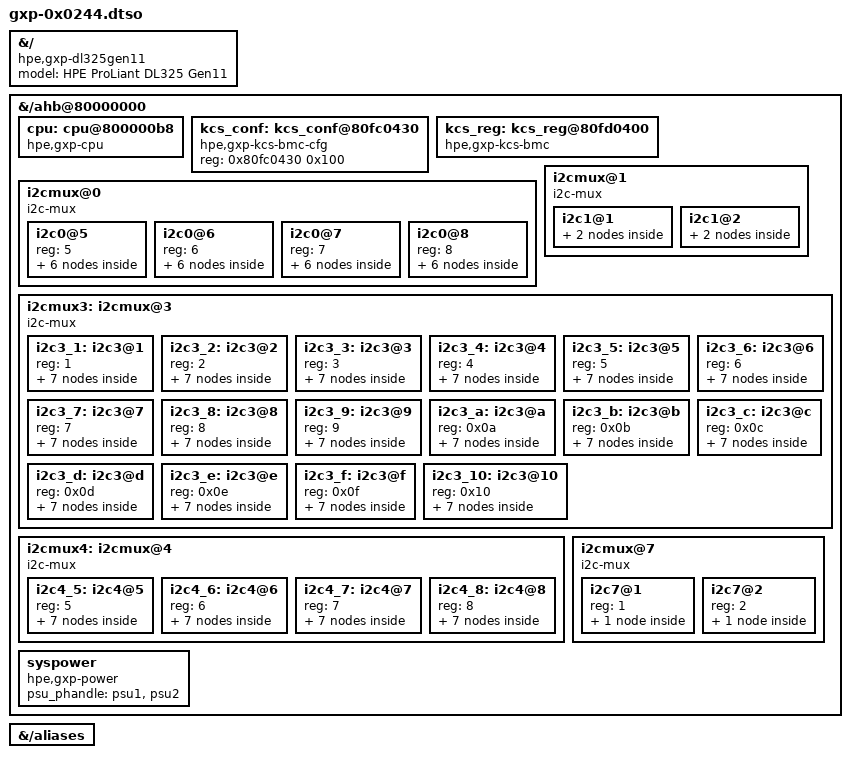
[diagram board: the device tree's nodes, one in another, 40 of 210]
/dts-v1/;
/plugin/;
&{/} {
    model = "HPE ProLiant DL325 Gen11";
    compatible = "hpe,gxp-dl325gen11", "hpe,gxp";
};
&{/ahb@80000000} {
    cpu: cpu@800000b8 {
        compatible = "hpe,gxp-cpu", "simple-mfd", "syscon";
        reg = <0x800000b8 0x2>;
        #gpio-cells = <2>;
        gpio-line-names =
        "CPU1_PRSNT", "CPU2_PRSNT", "CPU3_PRSNT", "CPU4_PRSNT", "", "", "","",
        "", "", "", "", "", "", "", "";
    };

    kcs_conf: kcs_conf@80fc0430 {
        compatible = "hpe,gxp-kcs-bmc-cfg", "simple-mfd", "syscon";
        reg = <0x80fc0430 0x100>;
    };

    kcs_reg: kcs_reg@80fd0400 {
        compatible = "hpe,gxp-kcs-bmc";
        reg = <0x80fd0400 0x8>;
        interrupts = <6>;
        interrupt-parent = <&vic1>;
        kcs-chan = <1>;
        status = "okay";
        kcs-bmc-cfg = <&kcs_conf>;
    };

    i2cmux@0 {
        compatible = "i2c-mux";
        i2c-parent = <&i2c0>;
        mux-controls = <&i2c_mux_ctrl 0>;
        #address-cells = <1>;
        #size-cells = <0>;
        i2c0@5 {
            reg = <5>;
            #address-cells = <1>;
            #size-cells = <0>;
            ddr5hub@50 {
                compatible = "jedec,spd5118";
                reg = <0x50>;
            };
            ddr5hub@51 {
                compatible = "jedec,spd5118";
                reg = <0x51>;
            };
            ddr5hub@52 {
                compatible = "jedec,spd5118";
                reg = <0x52>;
            };
            ddr5hub@53 {
                compatible = "jedec,spd5118";
                reg = <0x53>;
            };
            ddr5hub@54 {
                compatible = "jedec,spd5118";
                reg = <0x54>;
            };
            ddr5hub@55 {
                compatible = "jedec,spd5118";
                reg = <0x55>;
            };
        };
        i2c0@6 {
            reg = <6>;
            #address-cells = <1>;
            #size-cells = <0>;
            ddr5hub@50 {
                compatible = "jedec,spd5118";
                reg = <0x50>;
            };
            ddr5hub@51 {
                compatible = "jedec,spd5118";
                reg = <0x51>;
            };
            ddr5hub@52 {
                compatible = "jedec,spd5118";
                reg = <0x52>;
            };
            ddr5hub@53 {
                compatible = "jedec,spd5118";
                reg = <0x53>;
            };
            ddr5hub@54 {
                compatible = "jedec,spd5118";
                reg = <0x54>;
            };
            ddr5hub@55 {
                compatible = "jedec,spd5118";
                reg = <0x55>;
            };
        };
        i2c0@7 {
            reg = <7>;
            #address-cells = <1>;
            #size-cells = <0>;
            ddr5hub@50 {
                compatible = "jedec,spd5118";
                reg = <0x50>;
            };
            ddr5hub@51 {
                compatible = "jedec,spd5118";
                reg = <0x51>;
            };
            ddr5hub@52 {
                compatible = "jedec,spd5118";
                reg = <0x52>;
            };
            ddr5hub@53 {
                compatible = "jedec,spd5118";
                reg = <0x53>;
            };
            ddr5hub@54 {
                compatible = "jedec,spd5118";
                reg = <0x54>;
            };
            ddr5hub@55 {
                compatible = "jedec,spd5118";
                reg = <0x55>;
            };
        };
        i2c0@8 {
            reg = <8>;
            #address-cells = <1>;
            #size-cells = <0>;
            ddr5hub@50 {
                compatible = "jedec,spd5118";
                reg = <0x50>;
            };
            ddr5hub@51 {
                compatible = "jedec,spd5118";
                reg = <0x51>;
            };
            ddr5hub@52 {
                compatible = "jedec,spd5118";
                reg = <0x52>;
            };
            ddr5hub@53 {
                compatible = "jedec,spd5118";
                reg = <0x53>;
            };
            ddr5hub@54 {
                compatible = "jedec,spd5118";
                reg = <0x54>;
            };
            ddr5hub@55 {
                compatible = "jedec,spd5118";
                reg = <0x55>;
            };
        };
    };
    i2cmux@1 {
        compatible = "i2c-mux";
        i2c-parent = <&i2c1>;
        mux-controls = <&i2c_mux_ctrl 1>;
        #address-cells = <1>;
        #size-cells = <0>;
        i2c1@1 {
            reg = <1>;
            #address-cells = <1>;
            #size-cells = <0>;
            cpu-monitor = <1>;
            sbrmi@3c {
                compatible = "amd,sbrmi";
                dimm-count = <12>;
                reg = <0x3c>;
                sbrmi-supply = <&i2c_passthrough>;
            };
            sbtsi@4c {
                compatible = "amd,sbtsi";
                reg = <0x4c>;
                sbtsi-supply = <&i2c_passthrough>;
            };
        };
        i2c1@2 {
            reg = <2>;
            #address-cells = <1>;
            #size-cells = <0>;
            cpu-monitor = <2>;
            sbrmi@38 {
                compatible = "amd,sbrmi";
                dimm-count = <12>;
                reg = <0x38>;
                sbrmi-supply = <&i2c_passthrough>;
            };
            sbtsi@48 {
                compatible = "amd,sbtsi";
                reg = <0x48>;
                sbtsi-supply = <&i2c_passthrough>;
            };
        };
    };
    i2cmux3: i2cmux@3 {
        compatible = "i2c-mux";
        i2c-parent = <&i2c3>;
        mux-controls = <&i2c_mux_ctrl 3>;
        #address-cells = <1>;
        #size-cells = <0>;
        /* 5 7 9 b */
        i2c3_1: i2c3@1 {
            reg = <1>;
            #address-cells = <1>;
            #size-cells = <0>;
            piceeprom1: piceeprom@57 {
                compatible = "atmel,24c02";
                label = "piceeprom1";
                reg = <0x57>;
                vcc-supply = <&i2c_passthrough>;
            };
            ubm1: ubm@40 {
                compatible = "ubm4";
                vcc-supply = <&i2c_passthrough>;
                reg = <0x40>;
            };
            switch@72 {
                compatible = "nxp,pca9546";
                #address-cells = <1>;
                #size-cells = <0>;
                reg = <0x72>;
                vdd-supply = <&i2c_passthrough>;
                i2c-mux-idle-disconnect;
                drv1: i2c@0 {
                    #address-cells = <1>;
                    #size-cells = <0>;
                    reg = <0>;
                };
                drv2: i2c@1 {
                    #address-cells = <1>;
                    #size-cells = <0>;
                    reg = <1>;
                };
                i2c@2 {
                    #address-cells = <1>;
                    #size-cells = <0>;
                    reg = <2>;
                };
                i2c@3 {
                    #address-cells = <1>;
                    #size-cells = <0>;
                    reg = <3>;
                };
            };
        };
        i2c3_2: i2c3@2 {
            reg = <2>;
            #address-cells = <1>;
            #size-cells = <0>;
            piceeprom2: piceeprom@57 {
                compatible = "atmel,24c02";
                label = "piceeprom2";
                reg = <0x57>;
                vcc-supply = <&i2c_passthrough>;
            };
            ubm2: ubm@40 {
                compatible = "ubm4";
                vcc-supply = <&i2c_passthrough>;
                reg = <0x40>;
            };
            switch@72 {
                compatible = "nxp,pca9546";
                #address-cells = <1>;
                #size-cells = <0>;
                reg = <0x72>;
                vdd-supply = <&i2c_passthrough>;
                i2c-mux-idle-disconnect;
                drv3: i2c@0 {
                    #address-cells = <1>;
                    #size-cells = <0>;
                    reg = <0>;
                };
                drv4: i2c@1 {
                    #address-cells = <1>;
                    #size-cells = <0>;
                    reg = <1>;
                };
                i2c@2 {
                    #address-cells = <1>;
                    #size-cells = <0>;
                    reg = <2>;
                };
                i2c@3 {
                    #address-cells = <1>;
                    #size-cells = <0>;
                    reg = <3>;
                };
            };
        };
        i2c3_3: i2c3@3 {
            reg = <3>;
            #address-cells = <1>;
            #size-cells = <0>;
            piceeprom3: piceeprom@57 {
                compatible = "atmel,24c02";
                label = "piceeprom3";
                reg = <0x57>;
                vcc-supply = <&i2c_passthrough>;
            };
            ubm3: ubm@40 {
                compatible = "ubm4";
                vcc-supply = <&i2c_passthrough>;
                reg = <0x40>;
            };
            switch@72 {
                compatible = "nxp,pca9546";
                #address-cells = <1>;
                #size-cells = <0>;
                reg = <0x72>;
                vdd-supply = <&i2c_passthrough>;
                i2c-mux-idle-disconnect;
                drv5: i2c@0 {
                    #address-cells = <1>;
                    #size-cells = <0>;
                    reg = <0>;
                };
                drv6: i2c@1 {
                    #address-cells = <1>;
                    #size-cells = <0>;
                    reg = <1>;
                };
                i2c@2 {
                    #address-cells = <1>;
                    #size-cells = <0>;
                    reg = <2>;
                };
                i2c@3 {
                    #address-cells = <1>;
                    #size-cells = <0>;
                    reg = <3>;
                };
            };
        };
        i2c3_4: i2c3@4 {
            reg = <4>;
            #address-cells = <1>;
            #size-cells = <0>;
            piceeprom4: piceeprom@57 {
                compatible = "atmel,24c02";
                label = "piceeprom4";
                reg = <0x57>;
                vcc-supply = <&i2c_passthrough>;
            };
            ubm4: ubm@40 {
                compatible = "ubm4";
                vcc-supply = <&i2c_passthrough>;
                reg = <0x40>;
            };
            switch@72 {
                compatible = "nxp,pca9546";
                #address-cells = <1>;
                #size-cells = <0>;
                reg = <0x72>;
                vdd-supply = <&i2c_passthrough>;
                i2c-mux-idle-disconnect;
                drv7: i2c@0 {
                    #address-cells = <1>;
                    #size-cells = <0>;
                    reg = <0>;
                };
                drv8: i2c@1 {
                    #address-cells = <1>;
                    #size-cells = <0>;
                    reg = <1>;
                };
                i2c@2 {
                    #address-cells = <1>;
                    #size-cells = <0>;
                    reg = <2>;
                };
                i2c@3 {
                    #address-cells = <1>;
                    #size-cells = <0>;
                    reg = <3>;
                };
            };
        };
        i2c3_5: i2c3@5 {
            reg = <5>;
            #address-cells = <1>;
            #size-cells = <0>;
            piceeprom5: piceeprom@57 {
                compatible = "atmel,24c02";
                label = "piceeprom5";
                reg = <0x57>;
                vcc-supply = <&i2c_passthrough>;
            };
            ubm5: ubm@40 {
                compatible = "ubm4";
                vcc-supply = <&i2c_passthrough>;
                reg = <0x40>;
            };
            switch@72 {
                compatible = "nxp,pca9546";
                #address-cells = <1>;
                #size-cells = <0>;
                reg = <0x72>;
                vdd-supply = <&i2c_passthrough>;
                i2c-mux-idle-disconnect;
                drv9: i2c@0 {
                    #address-cells = <1>;
                    #size-cells = <0>;
                    reg = <0>;
                };
                drv10: i2c@1 {
                    #address-cells = <1>;
                    #size-cells = <0>;
                    reg = <1>;
                };
                i2c@2 {
                    #address-cells = <1>;
                    #size-cells = <0>;
                    reg = <2>;
                };
                i2c@3 {
                    #address-cells = <1>;
                    #size-cells = <0>;
                    reg = <3>;
                };
            };
        };
        i2c3_6: i2c3@6 {
            reg = <6>;
            #address-cells = <1>;
            #size-cells = <0>;
            piceeprom6: piceeprom@57 {
                compatible = "atmel,24c02";
                label = "piceeprom6";
                reg = <0x57>;
                vcc-supply = <&i2c_passthrough>;
            };
            ubm6: ubm@40 {
                compatible = "ubm4";
                vcc-supply = <&i2c_passthrough>;
                reg = <0x40>;
            };
            switch@72 {
                compatible = "nxp,pca9546";
                #address-cells = <1>;
                #size-cells = <0>;
                reg = <0x72>;
                vdd-supply = <&i2c_passthrough>;
                i2c-mux-idle-disconnect;
                drv11: i2c@0 {
                    #address-cells = <1>;
                    #size-cells = <0>;
                    reg = <0>;
                };
                drv12: i2c@1 {
                    #address-cells = <1>;
                    #size-cells = <0>;
                    reg = <1>;
                };
                i2c@2 {
                    #address-cells = <1>;
                    #size-cells = <0>;
                    reg = <2>;
                };
                i2c@3 {
                    #address-cells = <1>;
                    #size-cells = <0>;
                    reg = <3>;
                };
            };
        };
        i2c3_7: i2c3@7 {
            reg = <7>;
            #address-cells = <1>;
            #size-cells = <0>;
            piceeprom7: piceeprom@57 {
                compatible = "atmel,24c02";
                label = "piceeprom7";
                reg = <0x57>;
                vcc-supply = <&i2c_passthrough>;
            };
            ubm7: ubm@40 {
                compatible = "ubm4";
                vcc-supply = <&i2c_passthrough>;
                reg = <0x40>;
            };
            switch@72 {
                compatible = "nxp,pca9546";
                #address-cells = <1>;
                #size-cells = <0>;
                reg = <0x72>;
                vdd-supply = <&i2c_passthrough>;
                i2c-mux-idle-disconnect;
                drv13: i2c@0 {
                    #address-cells = <1>;
                    #size-cells = <0>;
                    reg = <0>;
                };
                drv14: i2c@1 {
                    #address-cells = <1>;
                    #size-cells = <0>;
                    reg = <1>;
                };
                i2c@2 {
                    #address-cells = <1>;
                    #size-cells = <0>;
                    reg = <2>;
                };
                i2c@3 {
                    #address-cells = <1>;
                    #size-cells = <0>;
                    reg = <3>;
                };
            };
        };
        i2c3_8: i2c3@8 {
            reg = <8>;
            #address-cells = <1>;
            #size-cells = <0>;
            piceeprom8: piceeprom@57 {
                compatible = "atmel,24c02";
                label = "piceeprom8";
                reg = <0x57>;
                vcc-supply = <&i2c_passthrough>;
            };
            ubm8: ubm@40 {
                compatible = "ubm4";
                vcc-supply = <&i2c_passthrough>;
                reg = <0x40>;
            };
            switch@72 {
                compatible = "nxp,pca9546";
                #address-cells = <1>;
                #size-cells = <0>;
                reg = <0x72>;
                vdd-supply = <&i2c_passthrough>;
                i2c-mux-idle-disconnect;
                drv15: i2c@0 {
                    #address-cells = <1>;
                    #size-cells = <0>;
                    reg = <0>;
                };
                drv16: i2c@1 {
                    #address-cells = <1>;
                    #size-cells = <0>;
                    reg = <1>;
                };
                i2c@2 {
                    #address-cells = <1>;
                    #size-cells = <0>;
                    reg = <2>;
                };
                i2c@3 {
                    #address-cells = <1>;
                    #size-cells = <0>;
                    reg = <3>;
                };
            };
        };
        i2c3_9: i2c3@9 {
            reg = <9>;
            #address-cells = <1>;
            #size-cells = <0>;
            piceeprom9: piceeprom@57 {
                compatible = "atmel,24c02";
                label = "piceeprom9";
                reg = <0x57>;
                vcc-supply = <&i2c_passthrough>;
            };
            ubm9: ubm@40 {
                compatible = "ubm4";
                vcc-supply = <&i2c_passthrough>;
                reg = <0x40>;
            };
            switch@72 {
                compatible = "nxp,pca9546";
                #address-cells = <1>;
                #size-cells = <0>;
                reg = <0x72>;
                vdd-supply = <&i2c_passthrough>;
                i2c-mux-idle-disconnect;
                drv17: i2c@0 {
                    #address-cells = <1>;
                    #size-cells = <0>;
                    reg = <0>;
                };
                drv18: i2c@1 {
                    #address-cells = <1>;
                    #size-cells = <0>;
                    reg = <1>;
                };
                i2c@2 {
                    #address-cells = <1>;
                    #size-cells = <0>;
                    reg = <2>;
                };
                i2c@3 {
                    #address-cells = <1>;
                    #size-cells = <0>;
                    reg = <3>;
                };
            };
        };
        i2c3_a: i2c3@a {
            reg = <0x0a>;
            #address-cells = <1>;
            #size-cells = <0>;
            piceeprom10: piceeprom@57 {
                compatible = "atmel,24c02";
                label = "piceeprom10";
                reg = <0x57>;
                vcc-supply = <&i2c_passthrough>;
            };
            ubm10: ubm@40 {
                compatible = "ubm4";
                vcc-supply = <&i2c_passthrough>;
                reg = <0x40>;
            };
            switch@72 {
                compatible = "nxp,pca9546";
                #address-cells = <1>;
                #size-cells = <0>;
                reg = <0x72>;
                vdd-supply = <&i2c_passthrough>;
                i2c-mux-idle-disconnect;
                drv19: i2c@0 {
                    #address-cells = <1>;
                    #size-cells = <0>;
                    reg = <0>;
                };
                drv20: i2c@1 {
                    #address-cells = <1>;
                    #size-cells = <0>;
                    reg = <1>;
                };
                i2c@2 {
                    #address-cells = <1>;
                    #size-cells = <0>;
                    reg = <2>;
                };
                i2c@3 {
                    #address-cells = <1>;
                    #size-cells = <0>;
                    reg = <3>;
                };
            };
        };
        i2c3_b: i2c3@b {
            reg = <0x0b>;
            #address-cells = <1>;
            #size-cells = <0>;
            piceeprom11: piceeprom@57 {
                compatible = "atmel,24c02";
                label = "piceeprom11";
                reg = <0x57>;
                vcc-supply = <&i2c_passthrough>;
            };
            ubm11: ubm@40 {
                compatible = "ubm4";
                vcc-supply = <&i2c_passthrough>;
                reg = <0x40>;
            };
            switch@72 {
                compatible = "nxp,pca9546";
                #address-cells = <1>;
                #size-cells = <0>;
                reg = <0x72>;
                vdd-supply = <&i2c_passthrough>;
                i2c-mux-idle-disconnect;
                drv21: i2c@0 {
                    #address-cells = <1>;
                    #size-cells = <0>;
                    reg = <0>;
                };
                drv22: i2c@1 {
                    #address-cells = <1>;
                    #size-cells = <0>;
                    reg = <1>;
                };
                i2c@2 {
                    #address-cells = <1>;
                    #size-cells = <0>;
                    reg = <2>;
                };
                i2c@3 {
                    #address-cells = <1>;
                    #size-cells = <0>;
                    reg = <3>;
                };
            };
        };
        i2c3_c: i2c3@c {
            reg = <0x0c>;
            #address-cells = <1>;
            #size-cells = <0>;
            piceeprom12: piceeprom@57 {
                compatible = "atmel,24c02";
                label = "piceeprom12";
                reg = <0x57>;
                vcc-supply = <&i2c_passthrough>;
            };
            ubm12: ubm@40 {
                compatible = "ubm4";
                vcc-supply = <&i2c_passthrough>;
                reg = <0x40>;
            };
            switch@72 {
                compatible = "nxp,pca9546";
                #address-cells = <1>;
                #size-cells = <0>;
                reg = <0x72>;
                vdd-supply = <&i2c_passthrough>;
                i2c-mux-idle-disconnect;
                drv23: i2c@0 {
                    #address-cells = <1>;
                    #size-cells = <0>;
                    reg = <0>;
                };
                drv24: i2c@1 {
                    #address-cells = <1>;
                    #size-cells = <0>;
                    reg = <1>;
                };
                i2c@2 {
                    #address-cells = <1>;
                    #size-cells = <0>;
                    reg = <2>;
                };
                i2c@3 {
                    #address-cells = <1>;
                    #size-cells = <0>;
                    reg = <3>;
                };
            };
        };
        i2c3_d: i2c3@d {
            reg = <0x0d>;
            #address-cells = <1>;
            #size-cells = <0>;
            piceeprom13: piceeprom@57 {
                compatible = "atmel,24c02";
                label = "piceeprom13";
                reg = <0x57>;
                vcc-supply = <&i2c_passthrough>;
            };
            ubm13: ubm@40 {
                compatible = "ubm4";
                vcc-supply = <&i2c_passthrough>;
                reg = <0x40>;
            };
            switch@72 {
                compatible = "nxp,pca9546";
                #address-cells = <1>;
                #size-cells = <0>;
                reg = <0x72>;
                vdd-supply = <&i2c_passthrough>;
                i2c-mux-idle-disconnect;
                drv25: i2c@0 {
                    #address-cells = <1>;
                    #size-cells = <0>;
                    reg = <0>;
                };
                drv26: i2c@1 {
                    #address-cells = <1>;
                    #size-cells = <0>;
                    reg = <1>;
                };
                i2c@2 {
                    #address-cells = <1>;
                    #size-cells = <0>;
                    reg = <2>;
                };
                i2c@3 {
                    #address-cells = <1>;
                    #size-cells = <0>;
                    reg = <3>;
                };
            };
        };
        i2c3_e: i2c3@e {
            reg = <0x0e>;
            #address-cells = <1>;
            #size-cells = <0>;
            piceeprom14: piceeprom@57 {
                compatible = "atmel,24c02";
                label = "piceeprom14";
                reg = <0x57>;
                vcc-supply = <&i2c_passthrough>;
            };
            ubm14: ubm@40 {
                compatible = "ubm4";
                vcc-supply = <&i2c_passthrough>;
                reg = <0x40>;
            };
            switch@72 {
                compatible = "nxp,pca9546";
                #address-cells = <1>;
                #size-cells = <0>;
                reg = <0x72>;
                vdd-supply = <&i2c_passthrough>;
                i2c-mux-idle-disconnect;
                drv27: i2c@0 {
                    #address-cells = <1>;
                    #size-cells = <0>;
                    reg = <0>;
                };
                drv28: i2c@1 {
                    #address-cells = <1>;
                    #size-cells = <0>;
                    reg = <1>;
                };
                i2c@2 {
                    #address-cells = <1>;
                    #size-cells = <0>;
                    reg = <2>;
                };
                i2c@3 {
                    #address-cells = <1>;
                    #size-cells = <0>;
                    reg = <3>;
                };
            };
        };
        i2c3_f: i2c3@f {
            reg = <0x0f>;
            #address-cells = <1>;
            #size-cells = <0>;
            piceeprom15: piceeprom@57 {
                compatible = "atmel,24c02";
                label = "piceeprom15";
                reg = <0x57>;
                vcc-supply = <&i2c_passthrough>;
            };
            ubm15: ubm@40 {
                compatible = "ubm4";
                vcc-supply = <&i2c_passthrough>;
                reg = <0x40>;
            };
            switch@72 {
                compatible = "nxp,pca9546";
                #address-cells = <1>;
                #size-cells = <0>;
                reg = <0x72>;
                vdd-supply = <&i2c_passthrough>;
                i2c-mux-idle-disconnect;
                drv29: i2c@0 {
                    #address-cells = <1>;
                    #size-cells = <0>;
                    reg = <0>;
                };
                drv30: i2c@1 {
                    #address-cells = <1>;
                    #size-cells = <0>;
                    reg = <1>;
                };
                i2c@2 {
                    #address-cells = <1>;
                    #size-cells = <0>;
                    reg = <2>;
                };
                i2c@3 {
                    #address-cells = <1>;
                    #size-cells = <0>;
                    reg = <3>;
                };
            };
        };
        i2c3_10: i2c3@10 {
            reg = <0x10>;
            #address-cells = <1>;
            #size-cells = <0>;
            piceeprom16: piceeprom@57 {
                compatible = "atmel,24c02";
                label = "piceeprom16";
                reg = <0x57>;
                vcc-supply = <&i2c_passthrough>;
            };
            ubm16: ubm@40 {
                compatible = "ubm4";
                vcc-supply = <&i2c_passthrough>;
                reg = <0x40>;
            };
            switch@72 {
                compatible = "nxp,pca9546";
                #address-cells = <1>;
                #size-cells = <0>;
                reg = <0x72>;
                vdd-supply = <&i2c_passthrough>;
                i2c-mux-idle-disconnect;
                drv31: i2c@0 {
                    #address-cells = <1>;
                    #size-cells = <0>;
                    reg = <0>;
                };
                drv32: i2c@1 {
                    #address-cells = <1>;
                    #size-cells = <0>;
                    reg = <1>;
                };
                i2c@2 {
                    #address-cells = <1>;
                    #size-cells = <0>;
                    reg = <2>;
                };
                i2c@3 {
                    #address-cells = <1>;
                    #size-cells = <0>;
                    reg = <3>;
                };
            };
        };
    };
    i2cmux4: i2cmux@4 {
        compatible = "i2c-mux";
        i2c-parent = <&i2c4>;
        mux-controls = <&i2c_mux_ctrl 4>;
        #address-cells = <1>;
        #size-cells = <0>;
        i2c4_5: i2c4@5 {
            reg = <5>;
            #address-cells = <1>;
            #size-cells = <0>;
            piceeprom17: piceeprom@57 {
                compatible = "atmel,24c02";
                label = "piceeprom17";
                reg = <0x57>;
                vcc-supply = <&i2c_passthrough>;
            };
            ubm17: ubm@40 {
                compatible = "ubm4";
                vcc-supply = <&i2c_passthrough>;
                reg = <0x40>;
            };
            switch@72 {
                compatible = "nxp,pca9546";
                #address-cells = <1>;
                #size-cells = <0>;
                reg = <0x72>;
                vdd-supply = <&i2c_passthrough>;
                i2c-mux-idle-disconnect;
                drv33: i2c@0 {
                    #address-cells = <1>;
                    #size-cells = <0>;
                    reg = <0>;
                };
                drv34: i2c@1 {
                    #address-cells = <1>;
                    #size-cells = <0>;
                    reg = <1>;
                };
                i2c@2 {
                    #address-cells = <1>;
                    #size-cells = <0>;
                    reg = <2>;
                };
                i2c@3 {
                    #address-cells = <1>;
                    #size-cells = <0>;
                    reg = <3>;
                };
            };
        };
        i2c4_6: i2c4@6 {
            reg = <6>;
            #address-cells = <1>;
            #size-cells = <0>;
            piceeprom18: piceeprom@57 {
                compatible = "atmel,24c02";
                label = "piceeprom18";
                reg = <0x57>;
                vcc-supply = <&i2c_passthrough>;
            };
            ubm18: ubm@40 {
                compatible = "ubm4";
                vcc-supply = <&i2c_passthrough>;
                reg = <0x40>;
            };
            switch@72 {
                compatible = "nxp,pca9546";
                #address-cells = <1>;
                #size-cells = <0>;
                reg = <0x72>;
                vdd-supply = <&i2c_passthrough>;
                i2c-mux-idle-disconnect;
                drv35: i2c@0 {
                    #address-cells = <1>;
                    #size-cells = <0>;
                    reg = <0>;
                };
                drv36: i2c@1 {
                    #address-cells = <1>;
                    #size-cells = <0>;
                    reg = <1>;
                };
                i2c@2 {
                    #address-cells = <1>;
                    #size-cells = <0>;
                    reg = <2>;
                };
                i2c@3 {
                    #address-cells = <1>;
                    #size-cells = <0>;
                    reg = <3>;
                };
            };
        };
        i2c4_7: i2c4@7 {
            reg = <7>;
            #address-cells = <1>;
            #size-cells = <0>;
            piceeprom19: piceeprom@57 {
                compatible = "atmel,24c02";
                label = "piceeprom19";
                reg = <0x57>;
                vcc-supply = <&i2c_passthrough>;
            };
            ubm19: ubm@40 {
                compatible = "ubm4";
                vcc-supply = <&i2c_passthrough>;
                reg = <0x40>;
            };
            switch@72 {
                compatible = "nxp,pca9546";
                #address-cells = <1>;
                #size-cells = <0>;
                reg = <0x72>;
                vdd-supply = <&i2c_passthrough>;
                i2c-mux-idle-disconnect;
                drv37: i2c@0 {
                    #address-cells = <1>;
                    #size-cells = <0>;
                    reg = <0>;
                };
                drv38: i2c@1 {
                    #address-cells = <1>;
                    #size-cells = <0>;
                    reg = <1>;
                };
                i2c@2 {
                    #address-cells = <1>;
                    #size-cells = <0>;
                    reg = <2>;
                };
                i2c@3 {
                    #address-cells = <1>;
                    #size-cells = <0>;
                    reg = <3>;
                };
            };
        };
        i2c4_8: i2c4@8 {
            reg = <8>;
            #address-cells = <1>;
            #size-cells = <0>;
            piceeprom20: piceeprom@57 {
                compatible = "atmel,24c02";
                label = "piceeprom20";
                reg = <0x57>;
                vcc-supply = <&i2c_passthrough>;
            };
            ubm20: ubm@40 {
                compatible = "ubm4";
                vcc-supply = <&i2c_passthrough>;
                reg = <0x40>;
            };
            switch@72 {
                compatible = "nxp,pca9546";
                #address-cells = <1>;
                #size-cells = <0>;
                reg = <0x72>;
                vdd-supply = <&i2c_passthrough>;
                i2c-mux-idle-disconnect;
                drv39: i2c@0 {
                    #address-cells = <1>;
                    #size-cells = <0>;
                    reg = <0>;
                };
                drv40: i2c@1 {
                    #address-cells = <1>;
                    #size-cells = <0>;
                    reg = <1>;
                };
                i2c@2 {
                    #address-cells = <1>;
                    #size-cells = <0>;
                    reg = <2>;
                };
                i2c@3 {
                    #address-cells = <1>;
                    #size-cells = <0>;
                    reg = <3>;
                };
            };
        };
    };
    /* add PSU mux */
    i2cmux@7 {
        compatible = "i2c-mux";
        i2c-parent = <&i2c7>;
        mux-controls = <&i2c_mux_ctrl 7>;
        #address-cells = <1>;
        #size-cells = <0>;
        i2c7@1 {
            reg = <1>;
            #address-cells = <1>;
            #size-cells = <0>;
            psu1: psu@58 {
                compatible = "hpe,gxp-psu";
                reg = <0x58>;
            };
        };
        i2c7@2 {
            reg = <2>;
            #address-cells = <1>;
            #size-cells = <0>;
            psu2: psu@59 {
                compatible = "hpe,gxp-psu";
                reg = <0x59>;
            };
        };
    };
    syspower: syspower {
        compatible = "hpe,gxp-power";
        psu_phandle = <&psu1>, <&psu2>;
    };
};
&{/aliases} {
    /* Base i2c controllers - fix bus numbers to match node index */
    i2c0 = "/ahb@80000000/i2c@c0002000";
    i2c1 = "/ahb@80000000/i2c@c0002100";
    i2c2 = "/ahb@80000000/i2c@c0002200";
    i2c3 = "/ahb@80000000/i2c@c0002300";
    i2c4 = "/ahb@80000000/i2c@c0002400";
    i2c5 = "/ahb@80000000/i2c@c0002500";
    i2c6 = "/ahb@80000000/i2c@c0002600";
    i2c7 = "/ahb@80000000/i2c@c0002700";
    i2c8 = "/ahb@80000000/i2c@c0002800";
    i2c9 = "/ahb@80000000/i2c@c0002900";
    /* DIMM SPD hub channels (i2cmux@0) */
    i2c10 = "/ahb@80000000/i2cmux@0/i2c0@5";
    i2c11 = "/ahb@80000000/i2cmux@0/i2c0@6";
    i2c12 = "/ahb@80000000/i2cmux@0/i2c0@7";
    i2c13 = "/ahb@80000000/i2cmux@0/i2c0@8";
    /* CPU telemetry channels (i2cmux@1, sbrmi/sbtsi) */
    i2c20 = "/ahb@80000000/i2cmux@1/i2c1@1";
    i2c21 = "/ahb@80000000/i2cmux@1/i2c1@2";
    /* PSU channels (i2cmux@7) */
    i2c30 = "/ahb@80000000/i2cmux@7/i2c7@1";
    i2c31 = "/ahb@80000000/i2cmux@7/i2c7@2";
    /* UBM backplane channel buses (FRU EEPROM 0x57) */
    i2c70 = "/ahb@80000000/i2cmux@3/i2c3@1";
    i2c71 = "/ahb@80000000/i2cmux@3/i2c3@2";
    i2c72 = "/ahb@80000000/i2cmux@3/i2c3@3";
    i2c73 = "/ahb@80000000/i2cmux@3/i2c3@4";
    i2c74 = "/ahb@80000000/i2cmux@3/i2c3@5";
    i2c75 = "/ahb@80000000/i2cmux@3/i2c3@6";
    i2c76 = "/ahb@80000000/i2cmux@3/i2c3@7";
    i2c77 = "/ahb@80000000/i2cmux@3/i2c3@8";
    i2c78 = "/ahb@80000000/i2cmux@3/i2c3@9";
    i2c79 = "/ahb@80000000/i2cmux@3/i2c3@a";
    i2c80 = "/ahb@80000000/i2cmux@3/i2c3@b";
    i2c81 = "/ahb@80000000/i2cmux@3/i2c3@c";
    i2c82 = "/ahb@80000000/i2cmux@3/i2c3@d";
    i2c83 = "/ahb@80000000/i2cmux@3/i2c3@e";
    i2c84 = "/ahb@80000000/i2cmux@3/i2c3@f";
    i2c85 = "/ahb@80000000/i2cmux@3/i2c3@10";
    i2c86 = "/ahb@80000000/i2cmux@4/i2c4@5";
    i2c87 = "/ahb@80000000/i2cmux@4/i2c4@6";
    i2c88 = "/ahb@80000000/i2cmux@4/i2c4@7";
    i2c89 = "/ahb@80000000/i2cmux@4/i2c4@8";
    /* PCA9546 drive-bay legs 0/1 (drive FRU 0x53 / NVMe temp 0x6a) */
    i2c100 = "/ahb@80000000/i2cmux@3/i2c3@1/switch@72/i2c@0";
    i2c101 = "/ahb@80000000/i2cmux@3/i2c3@1/switch@72/i2c@1";
    i2c102 = "/ahb@80000000/i2cmux@3/i2c3@2/switch@72/i2c@0";
    i2c103 = "/ahb@80000000/i2cmux@3/i2c3@2/switch@72/i2c@1";
    i2c104 = "/ahb@80000000/i2cmux@3/i2c3@3/switch@72/i2c@0";
    i2c105 = "/ahb@80000000/i2cmux@3/i2c3@3/switch@72/i2c@1";
    i2c106 = "/ahb@80000000/i2cmux@3/i2c3@4/switch@72/i2c@0";
    i2c107 = "/ahb@80000000/i2cmux@3/i2c3@4/switch@72/i2c@1";
    i2c108 = "/ahb@80000000/i2cmux@3/i2c3@5/switch@72/i2c@0";
    i2c109 = "/ahb@80000000/i2cmux@3/i2c3@5/switch@72/i2c@1";
    i2c110 = "/ahb@80000000/i2cmux@3/i2c3@6/switch@72/i2c@0";
    i2c111 = "/ahb@80000000/i2cmux@3/i2c3@6/switch@72/i2c@1";
    i2c112 = "/ahb@80000000/i2cmux@3/i2c3@7/switch@72/i2c@0";
    i2c113 = "/ahb@80000000/i2cmux@3/i2c3@7/switch@72/i2c@1";
    i2c114 = "/ahb@80000000/i2cmux@3/i2c3@8/switch@72/i2c@0";
    i2c115 = "/ahb@80000000/i2cmux@3/i2c3@8/switch@72/i2c@1";
    i2c116 = "/ahb@80000000/i2cmux@3/i2c3@9/switch@72/i2c@0";
    i2c117 = "/ahb@80000000/i2cmux@3/i2c3@9/switch@72/i2c@1";
    i2c118 = "/ahb@80000000/i2cmux@3/i2c3@a/switch@72/i2c@0";
    i2c119 = "/ahb@80000000/i2cmux@3/i2c3@a/switch@72/i2c@1";
    i2c120 = "/ahb@80000000/i2cmux@3/i2c3@b/switch@72/i2c@0";
    i2c121 = "/ahb@80000000/i2cmux@3/i2c3@b/switch@72/i2c@1";
    i2c122 = "/ahb@80000000/i2cmux@3/i2c3@c/switch@72/i2c@0";
    i2c123 = "/ahb@80000000/i2cmux@3/i2c3@c/switch@72/i2c@1";
    i2c124 = "/ahb@80000000/i2cmux@3/i2c3@d/switch@72/i2c@0";
    i2c125 = "/ahb@80000000/i2cmux@3/i2c3@d/switch@72/i2c@1";
    i2c126 = "/ahb@80000000/i2cmux@3/i2c3@e/switch@72/i2c@0";
    i2c127 = "/ahb@80000000/i2cmux@3/i2c3@e/switch@72/i2c@1";
    i2c128 = "/ahb@80000000/i2cmux@3/i2c3@f/switch@72/i2c@0";
    i2c129 = "/ahb@80000000/i2cmux@3/i2c3@f/switch@72/i2c@1";
    i2c130 = "/ahb@80000000/i2cmux@3/i2c3@10/switch@72/i2c@0";
    i2c131 = "/ahb@80000000/i2cmux@3/i2c3@10/switch@72/i2c@1";
    i2c132 = "/ahb@80000000/i2cmux@4/i2c4@5/switch@72/i2c@0";
    i2c133 = "/ahb@80000000/i2cmux@4/i2c4@5/switch@72/i2c@1";
    i2c134 = "/ahb@80000000/i2cmux@4/i2c4@6/switch@72/i2c@0";
    i2c135 = "/ahb@80000000/i2cmux@4/i2c4@6/switch@72/i2c@1";
    i2c136 = "/ahb@80000000/i2cmux@4/i2c4@7/switch@72/i2c@0";
    i2c137 = "/ahb@80000000/i2cmux@4/i2c4@7/switch@72/i2c@1";
    i2c138 = "/ahb@80000000/i2cmux@4/i2c4@8/switch@72/i2c@0";
    i2c139 = "/ahb@80000000/i2cmux@4/i2c4@8/switch@72/i2c@1";
    /* PCA9546 legs 2/3 - redundant mirrors, blocklisted in FruDevice */
    i2c200 = "/ahb@80000000/i2cmux@3/i2c3@1/switch@72/i2c@2";
    i2c201 = "/ahb@80000000/i2cmux@3/i2c3@1/switch@72/i2c@3";
    i2c202 = "/ahb@80000000/i2cmux@3/i2c3@2/switch@72/i2c@2";
    i2c203 = "/ahb@80000000/i2cmux@3/i2c3@2/switch@72/i2c@3";
    i2c204 = "/ahb@80000000/i2cmux@3/i2c3@3/switch@72/i2c@2";
    i2c205 = "/ahb@80000000/i2cmux@3/i2c3@3/switch@72/i2c@3";
    i2c206 = "/ahb@80000000/i2cmux@3/i2c3@4/switch@72/i2c@2";
    i2c207 = "/ahb@80000000/i2cmux@3/i2c3@4/switch@72/i2c@3";
    i2c208 = "/ahb@80000000/i2cmux@3/i2c3@5/switch@72/i2c@2";
    i2c209 = "/ahb@80000000/i2cmux@3/i2c3@5/switch@72/i2c@3";
    i2c210 = "/ahb@80000000/i2cmux@3/i2c3@6/switch@72/i2c@2";
    i2c211 = "/ahb@80000000/i2cmux@3/i2c3@6/switch@72/i2c@3";
    i2c212 = "/ahb@80000000/i2cmux@3/i2c3@7/switch@72/i2c@2";
    i2c213 = "/ahb@80000000/i2cmux@3/i2c3@7/switch@72/i2c@3";
    i2c214 = "/ahb@80000000/i2cmux@3/i2c3@8/switch@72/i2c@2";
    i2c215 = "/ahb@80000000/i2cmux@3/i2c3@8/switch@72/i2c@3";
    i2c216 = "/ahb@80000000/i2cmux@3/i2c3@9/switch@72/i2c@2";
    i2c217 = "/ahb@80000000/i2cmux@3/i2c3@9/switch@72/i2c@3";
    i2c218 = "/ahb@80000000/i2cmux@3/i2c3@a/switch@72/i2c@2";
    i2c219 = "/ahb@80000000/i2cmux@3/i2c3@a/switch@72/i2c@3";
    i2c220 = "/ahb@80000000/i2cmux@3/i2c3@b/switch@72/i2c@2";
    i2c221 = "/ahb@80000000/i2cmux@3/i2c3@b/switch@72/i2c@3";
    i2c222 = "/ahb@80000000/i2cmux@3/i2c3@c/switch@72/i2c@2";
    i2c223 = "/ahb@80000000/i2cmux@3/i2c3@c/switch@72/i2c@3";
    i2c224 = "/ahb@80000000/i2cmux@3/i2c3@d/switch@72/i2c@2";
    i2c225 = "/ahb@80000000/i2cmux@3/i2c3@d/switch@72/i2c@3";
    i2c226 = "/ahb@80000000/i2cmux@3/i2c3@e/switch@72/i2c@2";
    i2c227 = "/ahb@80000000/i2cmux@3/i2c3@e/switch@72/i2c@3";
    i2c228 = "/ahb@80000000/i2cmux@3/i2c3@f/switch@72/i2c@2";
    i2c229 = "/ahb@80000000/i2cmux@3/i2c3@f/switch@72/i2c@3";
    i2c230 = "/ahb@80000000/i2cmux@3/i2c3@10/switch@72/i2c@2";
    i2c231 = "/ahb@80000000/i2cmux@3/i2c3@10/switch@72/i2c@3";
    i2c232 = "/ahb@80000000/i2cmux@4/i2c4@5/switch@72/i2c@2";
    i2c233 = "/ahb@80000000/i2cmux@4/i2c4@5/switch@72/i2c@3";
    i2c234 = "/ahb@80000000/i2cmux@4/i2c4@6/switch@72/i2c@2";
    i2c235 = "/ahb@80000000/i2cmux@4/i2c4@6/switch@72/i2c@3";
    i2c236 = "/ahb@80000000/i2cmux@4/i2c4@7/switch@72/i2c@2";
    i2c237 = "/ahb@80000000/i2cmux@4/i2c4@7/switch@72/i2c@3";
    i2c238 = "/ahb@80000000/i2cmux@4/i2c4@8/switch@72/i2c@2";
    i2c239 = "/ahb@80000000/i2cmux@4/i2c4@8/switch@72/i2c@3";
};
